# CEC1712H_N2_SX register map
Vendor: Microchip
Registers are 32-bit, read-write, reset 0x0 unless marked. A register's access mark holds for its fields unless they carry their own. Addresses are absolute, and some are shared; only a register's first bit layout is shown; [hi:lo] are bit positions.

## TACH0
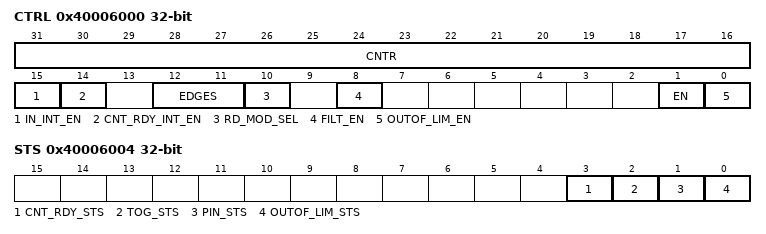
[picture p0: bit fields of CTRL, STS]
0x40006000 CTRL
  [31:16] CNTR — This 16-bit field contains the latched value of the internal Tach pulse counter, which may be configured by the Tach Reading Mode Select field to operate as a free-running counter or to be gated by the Tach input signal.
  [15] IN_INT_EN — TACH_INPUT_INT_EN 1=Enable Tach Input toggle interrupt from Tach block, 0=Disable Tach Input toggle interrupt from Tach block
  [14] CNT_RDY_INT_EN — COUNT_READY_INT_EN 1=Enable Count Ready interrupt from Tach block, 0=Disable Count Ready interrupt from Tach block
  [12:11] EDGES — TACH_EDGES A Tach signal is a square wave with a 50 percent duty cycle. Typically, two Tach periods represents one revolution of the fan. A Tach period consists of three Tach edges. This programmed value represents the number of Tach edges that will be used to determine the interval for which the number of 100kHz_Clk pulses will be counted. 11b=9 Tach edges (4 Tach periods). 10b=5 Tach edges (2 Tach periods). 01b=3 Tach edges (1 Tach period). 00b=2 Tach edges (1/2 Tach period)
  [10] RD_MOD_SEL — TACH_READING_MODE_SELECT. 1=Counter is incremented on the rising edge of the 100kHz_Clk input. The counter is latched into the TACHX_COUNTER field and reset when the programmed number of edges is detected. 0=Counter is incremented when Tach Input transitions from low-tohigh state (default)
  [8] FILT_EN — FILTER_ENABLE This filter is used to remove high frequency glitches from Tach Input. When this filter is enabled, Tach input pulses less than two 100kHz_- Clk periods wide get filtered. 1= Filter enabled. 0= Filter disabled (default). It is recommended that the Tach input filter always be enabled.
  [1] EN — TACH_ENABLE 1= TACH Monitoring enabled, clocks enabled. 0= TACH Idle, clocks gated
  [0] OUTOF_LIM_EN — TACH_OUT_OF_LIMIT_ENABLE This bit is used to enable the TACH_OUT_OF_LIMIT_STATUS bit in the TACHx Status Register to generate an interrupt event. 1=Enable interrupt output from Tach block. 0=Disable interrupt output from Tach block (default)
0x40006004 STS
  [3] CNT_RDY_STS — COUNT_READY_STATUS 1=Reading ready, 0=Reading not ready
  [2] TOG_STS — TOGGLE_STATUS 1=Tach Input changed state (this bit is set on a low-to-high or high-tolow transition), 0=Tach stable (R/WC)
  [1] PIN_STS — TACH_PIN_STATUS 1= Tach Input is high, 0= Tach Input is low
  [0] OUTOF_LIM_STS — TACH_OUT_OF_LIMIT_STATUS 1=Tach is outside of limits, 0=Tach is within limits (R/WC)
0x40006008 LIM_HI reset 0xFFFF
  [15:0] T_HIGH — This value is compared with the value in the TACHX_COUNTER field. If the value in the counter is greater than the value programmed in this register, the TACH_OUT_OF_LIMIT_STATUS bit will be set. The TACH_OUT_OF_LIMIT_STATUS status event may be enabled to generate an interrupt to the embedded controller via the TACH_OUT_OF_LIMIT_ENABLE bit in the TACHx Control Register.
0x4000600C LIM_LO
  [15:0] T_LOW — This value is compared with the value in the TACHX_COUNTER field of the TACHx Control Register. If the value in the counter is less than the value programmed in this register, the TACH_OUT_OF_LIMIT_STATUS bit will be set. The TACH_OUT_OF_LIMIT_STATUS status event may be enabled to generate an interrupt to the embedded controller via the TACH_OUT_OF_LIMIT_ENABLE bit in the TACHx. Control Register To disable the TACH_OUT_OF_LIMIT_STATUS low event, program 0000h into this register.

## TACH1
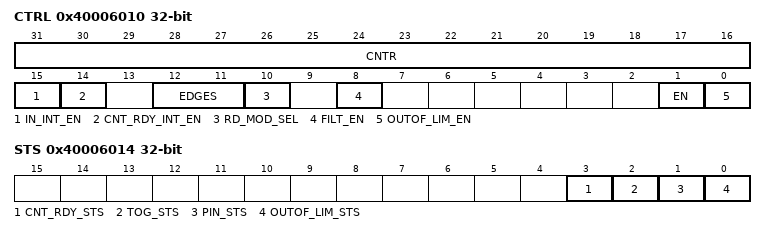
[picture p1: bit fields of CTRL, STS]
0x40006010 CTRL
  [31:16] CNTR — This 16-bit field contains the latched value of the internal Tach pulse counter, which may be configured by the Tach Reading Mode Select field to operate as a free-running counter or to be gated by the Tach input signal.
  [15] IN_INT_EN — TACH_INPUT_INT_EN 1=Enable Tach Input toggle interrupt from Tach block, 0=Disable Tach Input toggle interrupt from Tach block
  [14] CNT_RDY_INT_EN — COUNT_READY_INT_EN 1=Enable Count Ready interrupt from Tach block, 0=Disable Count Ready interrupt from Tach block
  [12:11] EDGES — TACH_EDGES A Tach signal is a square wave with a 50 percent duty cycle. Typically, two Tach periods represents one revolution of the fan. A Tach period consists of three Tach edges. This programmed value represents the number of Tach edges that will be used to determine the interval for which the number of 100kHz_Clk pulses will be counted. 11b=9 Tach edges (4 Tach periods). 10b=5 Tach edges (2 Tach periods). 01b=3 Tach edges (1 Tach period). 00b=2 Tach edges (1/2 Tach period)
  [10] RD_MOD_SEL — TACH_READING_MODE_SELECT. 1=Counter is incremented on the rising edge of the 100kHz_Clk input. The counter is latched into the TACHX_COUNTER field and reset when the programmed number of edges is detected. 0=Counter is incremented when Tach Input transitions from low-tohigh state (default)
  [8] FILT_EN — FILTER_ENABLE This filter is used to remove high frequency glitches from Tach Input. When this filter is enabled, Tach input pulses less than two 100kHz_- Clk periods wide get filtered. 1= Filter enabled. 0= Filter disabled (default). It is recommended that the Tach input filter always be enabled.
  [1] EN — TACH_ENABLE 1= TACH Monitoring enabled, clocks enabled. 0= TACH Idle, clocks gated
  [0] OUTOF_LIM_EN — TACH_OUT_OF_LIMIT_ENABLE This bit is used to enable the TACH_OUT_OF_LIMIT_STATUS bit in the TACHx Status Register to generate an interrupt event. 1=Enable interrupt output from Tach block. 0=Disable interrupt output from Tach block (default)
0x40006014 STS
  [3] CNT_RDY_STS — COUNT_READY_STATUS 1=Reading ready, 0=Reading not ready
  [2] TOG_STS — TOGGLE_STATUS 1=Tach Input changed state (this bit is set on a low-to-high or high-tolow transition), 0=Tach stable (R/WC)
  [1] PIN_STS — TACH_PIN_STATUS 1= Tach Input is high, 0= Tach Input is low
  [0] OUTOF_LIM_STS — TACH_OUT_OF_LIMIT_STATUS 1=Tach is outside of limits, 0=Tach is within limits (R/WC)
0x40006018 LIM_HI reset 0xFFFF
  [15:0] T_HIGH — This value is compared with the value in the TACHX_COUNTER field. If the value in the counter is greater than the value programmed in this register, the TACH_OUT_OF_LIMIT_STATUS bit will be set. The TACH_OUT_OF_LIMIT_STATUS status event may be enabled to generate an interrupt to the embedded controller via the TACH_OUT_OF_LIMIT_ENABLE bit in the TACHx Control Register.
0x4000601C LIM_LO
  [15:0] T_LOW — This value is compared with the value in the TACHX_COUNTER field of the TACHx Control Register. If the value in the counter is less than the value programmed in this register, the TACH_OUT_OF_LIMIT_STATUS bit will be set. The TACH_OUT_OF_LIMIT_STATUS status event may be enabled to generate an interrupt to the embedded controller via the TACH_OUT_OF_LIMIT_ENABLE bit in the TACHx. Control Register To disable the TACH_OUT_OF_LIMIT_STATUS low event, program 0000h into this register.
